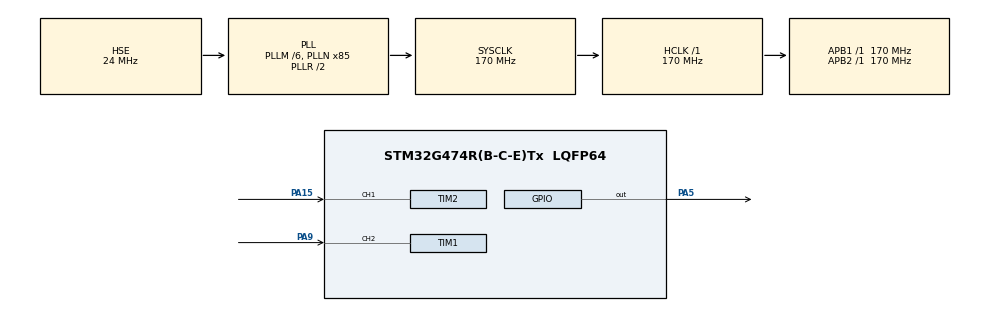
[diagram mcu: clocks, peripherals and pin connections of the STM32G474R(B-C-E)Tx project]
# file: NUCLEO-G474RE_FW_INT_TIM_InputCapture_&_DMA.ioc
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Dma.Request0=TIM2_CH1
Dma.TIM2_CH1.0.Direction=DMA_PERIPH_TO_MEMORY
Dma.TIM2_CH1.0.EventEnable=DISABLE
Dma.TIM2_CH1.0.Instance=DMA1_Channel1
Dma.TIM2_CH1.0.MemDataAlignment=DMA_MDATAALIGN_WORD
Dma.TIM2_CH1.0.MemInc=DMA_MINC_ENABLE
Dma.TIM2_CH1.0.Mode=DMA_CIRCULAR
Dma.TIM2_CH1.0.PeriphDataAlignment=DMA_PDATAALIGN_WORD
Dma.TIM2_CH1.0.PeriphInc=DMA_PINC_DISABLE
Dma.TIM2_CH1.0.Polarity=HAL_DMAMUX_REQ_GEN_RISING
Dma.TIM2_CH1.0.Priority=DMA_PRIORITY_LOW
Dma.TIM2_CH1.0.RequestNumber=1
Dma.TIM2_CH1.0.SignalID=NONE
Dma.TIM2_CH1.0.SyncEnable=DISABLE
Dma.TIM2_CH1.0.SyncPolarity=HAL_DMAMUX_SYNC_NO_EVENT
Dma.TIM2_CH1.0.SyncRequestNumber=1
Dma.TIM2_CH1.0.SyncSignalID=NONE
Mcu.Family=STM32G4
Mcu.Name=STM32G474R(B-C-E)Tx
Mcu.Package=LQFP64
NVIC.DMA1_Channel1_IRQn=true\:0\:0\:false\:false\:true\:false\:true
NVIC.PriorityGroup=NVIC_PRIORITYGROUP_4
NVIC.TIM1_CC_IRQn=true\:0\:0\:false\:false\:true\:true\:true
NVIC.TIM2_IRQn=true\:0\:0\:false\:false\:true\:true\:true
PA13.Mode=Trace_Asynchronous_SW
PA13.Signal=SYS_JTMS-SWDIO
PA14.Mode=Trace_Asynchronous_SW
PA14.Signal=SYS_JTCK-SWCLK
PA15.Signal=S_TIM2_CH1
PA5.Signal=GPIO_Output
PA9.Signal=S_TIM1_CH2
PB3.Mode=Trace_Asynchronous_SW
PB3.Signal=SYS_JTDO-SWO
PC14-OSC32_IN.Mode=LSE-External-Oscillator
PC14-OSC32_IN.Signal=RCC_OSC32_IN
PC15-OSC32_OUT.Mode=LSE-External-Oscillator
PC15-OSC32_OUT.Signal=RCC_OSC32_OUT
PF0-OSC_IN.Mode=HSE-External-Oscillator
PF0-OSC_IN.Signal=RCC_OSC_IN
PF1-OSC_OUT.Mode=HSE-External-Oscillator
PF1-OSC_OUT.Signal=RCC_OSC_OUT
ProjectManager.HeapSize=0x200
ProjectManager.StackSize=0x400
ProjectManager.TargetToolchain=STM32CubeIDE
RCC.ADC12Freq_Value=170000000
RCC.ADC345Freq_Value=170000000
RCC.AHBFreq_Value=170000000
RCC.APB1Freq_Value=170000000
RCC.APB1TimFreq_Value=170000000
RCC.APB2Freq_Value=170000000
RCC.APB2TimFreq_Value=170000000
RCC.CortexFreq_Value=170000000
RCC.EXTERNAL_CLOCK_VALUE=12288000
RCC.HCLKFreq_Value=170000000
RCC.HSE_VALUE=24000000
RCC.HSI48_VALUE=48000000
RCC.HSI_VALUE=16000000
RCC.PLLM=RCC_PLLM_DIV6
RCC.PLLN=85
RCC.PLLSourceVirtual=RCC_PLLSOURCE_HSE
RCC.SYSCLKFreq_VALUE=170000000
RCC.SYSCLKSource=RCC_SYSCLKSOURCE_PLLCLK
RCC.USBFreq_Value=170000000
RCC.VCOOutputFreq_Value=340000000
SH.S_TIM1_CH2.0=TIM1_CH2,Input_Capture2_from_TI2
SH.S_TIM2_CH1.0=TIM2_CH1,TriggerSource_TI1FP1
SH.S_TIM2_CH1.1=TIM2_CH1,Input_Capture1_from_TI1
SH.S_TIM2_CH1.2=TIM2_CH1
TIM1.AutoReloadPreload=TIM_AUTORELOAD_PRELOAD_DISABLE
TIM1.Channel-Input_Capture2_from_TI2=TIM_CHANNEL_2
TIM1.ClockDivision=TIM_CLOCKDIVISION_DIV1
TIM1.CounterMode=TIM_COUNTERMODE_UP
TIM1.ICFilter_CH2=0
TIM1.ICPolarity_CH2=TIM_INPUTCHANNELPOLARITY_RISING
TIM1.ICPrescaler-Input_Capture2_from_TI2=TIM_ICPSC_DIV1
TIM1.ICSelection-Input_Capture2_from_TI2=TIM_ICSELECTION_DIRECTTI
TIM1.Period=0xFFFF
TIM1.Prescaler=0
TIM1.RepetitionCounter=0
TIM1.TIM_MasterOutputTrigger=TIM_TRGO_RESET
TIM1.TIM_MasterOutputTrigger2=TIM_TRGO2_RESET
TIM1.TIM_MasterSlaveMode=TIM_MASTERSLAVEMODE_DISABLE
TIM2.AutoReloadPreload=TIM_AUTORELOAD_PRELOAD_DISABLE
TIM2.Channel-Input_Capture1_from_TI1=TIM_CHANNEL_1
TIM2.Prescaler=0
TIM2.TIM_MasterOutputTrigger=TIM_TRGO_RESET
TIM2.TIM_MasterSlaveMode=TIM_MASTERSLAVEMODE_DISABLE
VP_SYS_VS_DBSignals.Mode=DisableDeadBatterySignals
VP_TIM2_VS_ClockSourceINT.Mode=Internal
VP_TIM2_VS_ControllerModeReset.Mode=Reset Mode
board=custom

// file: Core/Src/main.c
/* USER CODE BEGIN Header */
/**
  ******************************************************************************
  * @file    TIM/TIM_InputCapture/Src/main.c
  * @author  MCD Application Team
  * @brief   This example shows how to use the TIM peripheral to measure only
  *          the frequency  of an external signal.
  ******************************************************************************
  * @attention
  *
  * <h2><center>&copy; Copyright (c) 2019 STMicroelectronics.
  * All rights reserved.</center></h2>
  *
  * This software component is licensed by ST under BSD 3-Clause license,
  * the "License"; You may not use this file except in compliance with the
  * License. You may obtain a copy of the License at:
  *                        opensource.org/licenses/BSD-3-Clause
  *
  ******************************************************************************
  */
/* USER CODE END Header */
#include "main.h"

TIM_HandleTypeDef htim1;
TIM_HandleTypeDef htim2;
DMA_HandleTypeDef hdma_tim2_ch1;

/* USER CODE BEGIN PV */
/* Captured Values */
uint32_t uwIC2Value1 = 0;
uint32_t uwIC2Value2 = 0;
uint32_t uwDiffCapture = 0;
uint32_t uwTIM2_UP_DMA;
uint32_t uwTIM2_CH1_DMA;

/* Capture index */
uint16_t uhCaptureIndex = 0;

/* Frequency Value */
uint32_t PCLK2Freq, uwFrequency = 0;

/* USER CODE END PV */

void SystemClock_Config(void);
static void MX_GPIO_Init(void);
static void MX_DMA_Init(void);
static void MX_TIM1_Init(void);
static void MX_TIM2_Init(void);

int main(void)
{
  /* USER CODE BEGIN 1 */

  /* STM32G4xx HAL library initialization:
       - Configure the Flash prefetch
       - Systick timer is configured by default as source of time base, but user
         can eventually implement his proper time base source (a general purpose
         timer for example or other time source), keeping in mind that Time base
         duration should be kept 1ms since PPP_TIMEOUT_VALUEs are defined and
         handled in milliseconds basis.
       - Set NVIC Group Priority to 4
       - Low Level Initialization
     */
  /* USER CODE END 1 */

  /* MCU Configuration--------------------------------------------------------*/

  /* Reset of all peripherals, Initializes the Flash interface and the Systick. */
  HAL_Init();

  /* Configure the system clock */
  SystemClock_Config();

  /* USER CODE BEGIN SysInit */

  /* Configure LED2 */
  //BSP_LED_Init(LED2);

  /* USER CODE END SysInit */

  /* Initialize all configured peripherals */
  MX_GPIO_Init();
  MX_DMA_Init();
  MX_TIM1_Init();
  MX_TIM2_Init();

  /* Infinite loop */
  /* USER CODE BEGIN WHILE */

  /* TIM1 configuration: Input Capture mode ---------------------
     The external signal is connected to TIM1 CH2 pin (PA9)
     The Rising edge is used as active edge,
     The TIM1 CCR2 is used to compute the frequency value
  ------------------------------------------------------------ */

  /*## Start the Input Capture in interrupt mode ##########################*/
  if(HAL_TIM_IC_Start_IT(&htim1, TIM_CHANNEL_2) != HAL_OK)
  {
    /* Starting Error */
    Error_Handler();
  }

//  if(HAL_TIM_IC_Start_IT(&htim2, TIM_CHANNEL_1) != HAL_OK)
//  {
//    /* Starting Error */
//    Error_Handler();
//  }

  // HAL_StatusTypeDef HAL_TIM_IC_Start_DMA(TIM_HandleTypeDef *htim, uint32_t Channel, uint32_t *pData, uint16_t Length)
//  if(HAL_TIM_IC_Start_DMA(&htim2, TIM_CHANNEL_1, &uwTIM2_UP_DMA, 1) != HAL_OK)
//  {
//    /* Starting Error */
//    Error_Handler();
//  }

  if(HAL_TIM_IC_Start_DMA(&htim2, TIM_CHANNEL_1, &uwTIM2_CH1_DMA, 1) != HAL_OK)
  {
    /* Starting Error */
    Error_Handler();
  }

  while (1)
  {
	  HAL_Delay(200);
	  HAL_GPIO_TogglePin(GPIOA, GPIO_PIN_5);

    /* USER CODE END WHILE */

  }
}

void SystemClock_Config(void)
{
  RCC_OscInitTypeDef RCC_OscInitStruct = {0};
  RCC_ClkInitTypeDef RCC_ClkInitStruct = {0};

  /** Configure the main internal regulator output voltage
  */
  HAL_PWREx_ControlVoltageScaling(PWR_REGULATOR_VOLTAGE_SCALE1_BOOST);
  /** Initializes the RCC Oscillators according to the specified parameters
  * in the RCC_OscInitTypeDef structure.
  */
  RCC_OscInitStruct.OscillatorType = RCC_OSCILLATORTYPE_HSE;
  RCC_OscInitStruct.HSEState = RCC_HSE_ON;
  RCC_OscInitStruct.PLL.PLLState = RCC_PLL_ON;
  RCC_OscInitStruct.PLL.PLLSource = RCC_PLLSOURCE_HSE;
  RCC_OscInitStruct.PLL.PLLM = RCC_PLLM_DIV6;
  RCC_OscInitStruct.PLL.PLLN = 85;
  RCC_OscInitStruct.PLL.PLLP = RCC_PLLP_DIV2;
  RCC_OscInitStruct.PLL.PLLQ = RCC_PLLQ_DIV2;
  RCC_OscInitStruct.PLL.PLLR = RCC_PLLR_DIV2;
  if (HAL_RCC_OscConfig(&RCC_OscInitStruct) != HAL_OK)
  {
    Error_Handler();
  }
  /** Initializes the CPU, AHB and APB buses clocks
  */
  RCC_ClkInitStruct.ClockType = RCC_CLOCKTYPE_HCLK|RCC_CLOCKTYPE_SYSCLK
                              |RCC_CLOCKTYPE_PCLK1|RCC_CLOCKTYPE_PCLK2;
  RCC_ClkInitStruct.SYSCLKSource = RCC_SYSCLKSOURCE_PLLCLK;
  RCC_ClkInitStruct.AHBCLKDivider = RCC_SYSCLK_DIV1;
  RCC_ClkInitStruct.APB1CLKDivider = RCC_HCLK_DIV1;
  RCC_ClkInitStruct.APB2CLKDivider = RCC_HCLK_DIV1;

  if (HAL_RCC_ClockConfig(&RCC_ClkInitStruct, FLASH_LATENCY_4) != HAL_OK)
  {
    Error_Handler();
  }
}

static void MX_TIM1_Init(void)
{

  TIM_MasterConfigTypeDef sMasterConfig = {0};
  TIM_IC_InitTypeDef sConfigIC = {0};
  TIM_BreakDeadTimeConfigTypeDef sBreakDeadTimeConfig = {0};

  htim1.Instance = TIM1;
  htim1.Init.Prescaler = 0;
  htim1.Init.CounterMode = TIM_COUNTERMODE_UP;
  htim1.Init.Period = 0xFFFF;
  htim1.Init.ClockDivision = TIM_CLOCKDIVISION_DIV1;
  htim1.Init.RepetitionCounter = 0;
  htim1.Init.AutoReloadPreload = TIM_AUTORELOAD_PRELOAD_DISABLE;
  if (HAL_TIM_IC_Init(&htim1) != HAL_OK)
  {
    Error_Handler();
  }
  sMasterConfig.MasterOutputTrigger = TIM_TRGO_RESET;
  sMasterConfig.MasterOutputTrigger2 = TIM_TRGO2_RESET;
  sMasterConfig.MasterSlaveMode = TIM_MASTERSLAVEMODE_DISABLE;
  if (HAL_TIMEx_MasterConfigSynchronization(&htim1, &sMasterConfig) != HAL_OK)
  {
    Error_Handler();
  }
  sConfigIC.ICPolarity = TIM_INPUTCHANNELPOLARITY_RISING;
  sConfigIC.ICSelection = TIM_ICSELECTION_DIRECTTI;
  sConfigIC.ICPrescaler = TIM_ICPSC_DIV1;
  sConfigIC.ICFilter = 0;
  if (HAL_TIM_IC_ConfigChannel(&htim1, &sConfigIC, TIM_CHANNEL_2) != HAL_OK)
  {
    Error_Handler();
  }
  sBreakDeadTimeConfig.BreakAFMode = TIM_BREAK_AFMODE_INPUT;
  sBreakDeadTimeConfig.Break2AFMode = TIM_BREAK_AFMODE_INPUT;
  if (HAL_TIMEx_ConfigBreakDeadTime(&htim1, &sBreakDeadTimeConfig) != HAL_OK)
  {
    Error_Handler();
  }

}

static void MX_TIM2_Init(void)
{

  TIM_ClockConfigTypeDef sClockSourceConfig = {0};
  TIM_SlaveConfigTypeDef sSlaveConfig = {0};
  TIM_MasterConfigTypeDef sMasterConfig = {0};
  TIM_IC_InitTypeDef sConfigIC = {0};

  htim2.Instance = TIM2;
  htim2.Init.Prescaler = 0;
  htim2.Init.CounterMode = TIM_COUNTERMODE_UP;
  htim2.Init.Period = 4.294967295E9;
  htim2.Init.ClockDivision = TIM_CLOCKDIVISION_DIV1;
  htim2.Init.AutoReloadPreload = TIM_AUTORELOAD_PRELOAD_DISABLE;
  if (HAL_TIM_Base_Init(&htim2) != HAL_OK)
  {
    Error_Handler();
  }
  sClockSourceConfig.ClockSource = TIM_CLOCKSOURCE_INTERNAL;
  if (HAL_TIM_ConfigClockSource(&htim2, &sClockSourceConfig) != HAL_OK)
  {
    Error_Handler();
  }
  if (HAL_TIM_IC_Init(&htim2) != HAL_OK)
  {
    Error_Handler();
  }
  sSlaveConfig.SlaveMode = TIM_SLAVEMODE_RESET;
  sSlaveConfig.InputTrigger = TIM_TS_TI1FP1;
  sSlaveConfig.TriggerPolarity = TIM_INPUTCHANNELPOLARITY_RISING;
  sSlaveConfig.TriggerFilter = 0;
  if (HAL_TIM_SlaveConfigSynchro(&htim2, &sSlaveConfig) != HAL_OK)
  {
    Error_Handler();
  }
  sMasterConfig.MasterOutputTrigger = TIM_TRGO_RESET;
  sMasterConfig.MasterSlaveMode = TIM_MASTERSLAVEMODE_DISABLE;
  if (HAL_TIMEx_MasterConfigSynchronization(&htim2, &sMasterConfig) != HAL_OK)
  {
    Error_Handler();
  }
  sConfigIC.ICPolarity = TIM_INPUTCHANNELPOLARITY_RISING;
  sConfigIC.ICSelection = TIM_ICSELECTION_DIRECTTI;
  sConfigIC.ICPrescaler = TIM_ICPSC_DIV1;
  sConfigIC.ICFilter = 0;
  if (HAL_TIM_IC_ConfigChannel(&htim2, &sConfigIC, TIM_CHANNEL_1) != HAL_OK)
  {
    Error_Handler();
  }

}

static void MX_DMA_Init(void)
{

  /* DMA controller clock enable */
  __HAL_RCC_DMAMUX1_CLK_ENABLE();
  __HAL_RCC_DMA1_CLK_ENABLE();

  /* DMA interrupt init */
  /* DMA1_Channel1_IRQn interrupt configuration */
  HAL_NVIC_SetPriority(DMA1_Channel1_IRQn, 0, 0);
  HAL_NVIC_EnableIRQ(DMA1_Channel1_IRQn);

}

static void MX_GPIO_Init(void)
{
  GPIO_InitTypeDef GPIO_InitStruct = {0};

  /* GPIO Ports Clock Enable */
  __HAL_RCC_GPIOC_CLK_ENABLE();
  __HAL_RCC_GPIOF_CLK_ENABLE();
  __HAL_RCC_GPIOA_CLK_ENABLE();
  __HAL_RCC_GPIOB_CLK_ENABLE();

  /*Configure GPIO pin Output Level */
  HAL_GPIO_WritePin(GPIOA, GPIO_PIN_5, GPIO_PIN_RESET);

  /*Configure GPIO pin : PA5 */
  GPIO_InitStruct.Pin = GPIO_PIN_5;
  GPIO_InitStruct.Mode = GPIO_MODE_OUTPUT_PP;
  GPIO_InitStruct.Pull = GPIO_NOPULL;
  GPIO_InitStruct.Speed = GPIO_SPEED_FREQ_LOW;
  HAL_GPIO_Init(GPIOA, &GPIO_InitStruct);

}

/* USER CODE BEGIN 4 */
/**
  * @brief  Input capture callback in non blocking mode
  * @param  htim : htim handle
  * @retval None
  */
void HAL_TIM_IC_CaptureCallback(TIM_HandleTypeDef *htim)
{
  if (htim->Channel == HAL_TIM_ACTIVE_CHANNEL_2)
  {
    if(uhCaptureIndex == 0)
    {
      /* Get the 1st Input Capture value */
      uwIC2Value1 = HAL_TIM_ReadCapturedValue(htim, TIM_CHANNEL_2);
      uhCaptureIndex = 1;
    }
    else if(uhCaptureIndex == 1)
    {
      /* Get the 2nd Input Capture value */
      uwIC2Value2 = HAL_TIM_ReadCapturedValue(htim, TIM_CHANNEL_2);

      /* Capture computation */
      if (uwIC2Value2 > uwIC2Value1)
      {
        uwDiffCapture = (uwIC2Value2 - uwIC2Value1);
      }
      else if (uwIC2Value2 < uwIC2Value1)
      {
        /* 0xFFFF is max TIM1_CCRx value */
        uwDiffCapture = ((0xFFFF - uwIC2Value1) + uwIC2Value2) + 1;
      }
      else
      {
        /* If capture values are equal, we have reached the limit of frequency
           measures */
        Error_Handler();
      }

      /* Frequency computation: for this example TIMx (TIM1) is clocked by
         APB2Clk */
      PCLK2Freq = HAL_RCC_GetPCLK2Freq();
      uwFrequency = HAL_RCC_GetPCLK2Freq() / uwDiffCapture;
      uhCaptureIndex = 0;
    }
  }
}

/* USER CODE END 4 */

void Error_Handler(void)
{
  /* USER CODE BEGIN Error_Handler_Debug */
  /* Turn LED2 on */
  //BSP_LED_On(LED2);
	HAL_GPIO_WritePin(GPIOA, GPIO_PIN_5, SET);
  while(1)
  {
  }
  /* USER CODE END Error_Handler_Debug */
}

/************************ (C) COPYRIGHT STMicroelectronics *****END OF FILE****/
